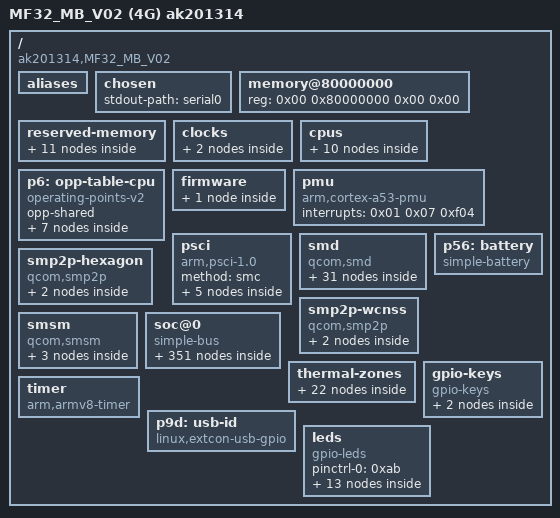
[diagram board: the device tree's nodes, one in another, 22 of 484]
/dts-v1/;

/ {
	interrupt-parent = <0x01>;
	#address-cells = <0x02>;
	#size-cells = <0x02>;
	chassis-type = "embedded";
	model = "MF32_MB_V02 (4G) ak201314";
	compatible = "ak201314,MF32_MB_V02", "qcom,msm8916";

	aliases {
		mmc0 = "/soc@0/mmc@7824000";
		mmc1 = "/soc@0/mmc@7864000";
		serial0 = "/soc@0/serial@78b0000";
	};

	chosen {
		stdout-path = "serial0";
	};

	memory@80000000 {
		device_type = "memory";
		reg = <0x00 0x80000000 0x00 0x00>;
	};

	reserved-memory {
		#address-cells = <0x02>;
		#size-cells = <0x02>;
		ranges;

		tz-apps@86000000 {
			reg = <0x00 0x86000000 0x00 0x300000>;
			no-map;
		};

		smem@86300000 {
			compatible = "qcom,smem";
			reg = <0x00 0x86300000 0x00 0x100000>;
			no-map;
			hwlocks = <&p2 0x03>;
			qcom,rpm-msg-ram = <0x03>;
		};

		hypervisor@86400000 {
			reg = <0x00 0x86400000 0x00 0x100000>;
			no-map;
		};

		tz@86500000 {
			reg = <0x00 0x86500000 0x00 0x180000>;
			no-map;
		};

		reserved@86680000 {
			reg = <0x00 0x86680000 0x00 0x80000>;
			no-map;
		};

		rmtfs@86700000 {
			compatible = "qcom,rmtfs-mem";
			reg = <0x00 0x86700000 0x00 0xe0000>;
			no-map;
			qcom,client-id = <0x01>;
		};

		rfsa@867e0000 {
			reg = <0x00 0x867e0000 0x00 0x20000>;
			no-map;
		};

		p64: mpss@86800000 {
			reg = <0x00 0x86800000 0x00 0x5500000>;
			no-map;
			phandle = <0x64>;
		};

		p9f: wcnss@8df00000 {
			reg = <0x00 0x8df00000 0x00 0x600000>;
			no-map;
			phandle = <0x9f>;
		};

		p55: venus@8e500000 {
			reg = <0x00 0x8e500000 0x00 0x100000>;
			no-map;
			phandle = <0x55>;
			status = "disabled";
		};

		p63: mba@8ea00000 {
			reg = <0x00 0x8ea00000 0x00 0x100000>;
			no-map;
			phandle = <0x63>;
		};
	};

	clocks {

		p1b: xo-board {
			compatible = "fixed-clock";
			#clock-cells = <0x00>;
			clock-frequency = <0x124f800>;
			phandle = <0x1b>;
		};

		p4a: sleep-clk {
			compatible = "fixed-clock";
			#clock-cells = <0x00>;
			clock-frequency = <0x8000>;
			phandle = <0x4a>;
		};
	};

	cpus {
		#address-cells = <0x01>;
		#size-cells = <0x00>;

		p3d: cpu@0 {
			device_type = "cpu";
			compatible = "arm,cortex-a53";
			reg = <0x00>;
			next-level-cache = <0x04>;
			enable-method = "psci";
			clocks = <&p5>;
			operating-points-v2 = <0x06>;
			#cooling-cells = <0x02>;
			power-domains = <&p7>;
			power-domain-names = "psci";
			qcom,acc = <0x08>;
			qcom,saw = <0x09>;
			phandle = <0x3d>;
		};

		p3e: cpu@1 {
			device_type = "cpu";
			compatible = "arm,cortex-a53";
			reg = <0x01>;
			next-level-cache = <0x04>;
			enable-method = "psci";
			clocks = <&p5>;
			operating-points-v2 = <0x06>;
			#cooling-cells = <0x02>;
			power-domains = <&pa>;
			power-domain-names = "psci";
			qcom,acc = <0x0b>;
			qcom,saw = <0x0c>;
			phandle = <0x3e>;
		};

		p3f: cpu@2 {
			device_type = "cpu";
			compatible = "arm,cortex-a53";
			reg = <0x02>;
			next-level-cache = <0x04>;
			enable-method = "psci";
			clocks = <&p5>;
			operating-points-v2 = <0x06>;
			#cooling-cells = <0x02>;
			power-domains = <&pd>;
			power-domain-names = "psci";
			qcom,acc = <0x0e>;
			qcom,saw = <0x0f>;
			phandle = <0x3f>;
		};

		p40: cpu@3 {
			device_type = "cpu";
			compatible = "arm,cortex-a53";
			reg = <0x03>;
			next-level-cache = <0x04>;
			enable-method = "psci";
			clocks = <&p5>;
			operating-points-v2 = <0x06>;
			#cooling-cells = <0x02>;
			power-domains = <&p10>;
			power-domain-names = "psci";
			qcom,acc = <0x11>;
			qcom,saw = <0x12>;
			phandle = <0x40>;
		};

		p4: l2-cache {
			compatible = "cache";
			cache-level = <0x02>;
			phandle = <0x04>;
		};

		idle-states {
			entry-method = "psci";

			p18: cpu-sleep-0 {
				compatible = "arm,idle-state";
				idle-state-name = "standalone-power-collapse";
				arm,psci-suspend-param = <0x40000002>;
				entry-latency-us = <0x82>;
				exit-latency-us = <0x96>;
				min-residency-us = <0x7d0>;
				local-timer-stop;
				phandle = <0x18>;
			};
		};

		domain-idle-states {

			p19: cluster-retention {
				compatible = "domain-idle-state";
				arm,psci-suspend-param = <0x41000012>;
				entry-latency-us = <0x1f4>;
				exit-latency-us = <0x1f4>;
				min-residency-us = <0x7d0>;
				phandle = <0x19>;
			};

			p1a: cluster-gdhs {
				compatible = "domain-idle-state";
				arm,psci-suspend-param = <0x41000032>;
				entry-latency-us = <0x7d0>;
				exit-latency-us = <0x7d0>;
				min-residency-us = <0x1770>;
				phandle = <0x1a>;
			};
		};
	};

	p6: opp-table-cpu {
		compatible = "operating-points-v2";
		opp-shared;
		phandle = <0x06>;

		opp-200000000 {
			opp-hz = <0x00 0xbebc200>;
		};

		opp-400000000 {
			opp-hz = <0x00 0x17d78400>;
		};

		opp-800000000 {
			opp-hz = <0x00 0x2faf0800>;
		};

		opp-998400000 {
			opp-hz = <0x00 0x3b826000>;
		};

		opp-1094400000 {
			opp-hz = <0x00 0x413b3800>;
		};

		opp-1152000000 {
			opp-hz = <0x00 0x44aa2000>;
		};

		opp-1209600000 {
			opp-hz = <0x00 0x48190800>;
		};
	};

	firmware {

		p61: scm {
			compatible = "qcom,scm-msm8916", "qcom,scm";
			clocks = <&p13 0x68 &p13 0x67 &p13 0x66>;
			clock-names = "core", "bus", "iface";
			#reset-cells = <0x01>;
			qcom,dload-mode = <0x14 0x6100>;
			phandle = <0x61>;
		};
	};

	pmu {
		compatible = "arm,cortex-a53-pmu";
		interrupts = <0x01 0x07 0xf04>;
	};

	psci {
		compatible = "arm,psci-1.0";
		method = "smc";

		p7: power-domain-cpu0 {
			#power-domain-cells = <0x00>;
			power-domains = <&p17>;
			domain-idle-states = <0x18>;
			phandle = <0x07>;
		};

		pa: power-domain-cpu1 {
			#power-domain-cells = <0x00>;
			power-domains = <&p17>;
			domain-idle-states = <0x18>;
			phandle = <0x0a>;
		};

		pd: power-domain-cpu2 {
			#power-domain-cells = <0x00>;
			power-domains = <&p17>;
			domain-idle-states = <0x18>;
			phandle = <0x0d>;
		};

		p10: power-domain-cpu3 {
			#power-domain-cells = <0x00>;
			power-domains = <&p17>;
			domain-idle-states = <0x18>;
			phandle = <0x10>;
		};

		p17: power-domain-cluster {
			#power-domain-cells = <0x00>;
			domain-idle-states = <0x19 0x1a>;
			phandle = <0x17>;
		};
	};

	smd {
		compatible = "qcom,smd";

		rpm {
			interrupts = <0x00 0xa8 0x01>;
			qcom,ipc = <0x05 0x08 0x00>;
			qcom,smd-edge = <0x0f>;

			rpm-requests {
				compatible = "qcom,rpm-msm8916";
				qcom,smd-channels = "rpm_requests";

				p1f: clock-controller {
					compatible = "qcom,rpmcc-msm8916", "qcom,rpmcc";
					#clock-cells = <0x01>;
					clocks = <&p1b>;
					clock-names = "xo";
					phandle = <0x1f>;
				};

				p5f: power-controller {
					compatible = "qcom,msm8916-rpmpd";
					#power-domain-cells = <0x01>;
					operating-points-v2 = <0x1c>;
					phandle = <0x5f>;

					p1c: opp-table {
						compatible = "operating-points-v2";
						phandle = <0x1c>;

						opp1 {
							opp-level = <0x01>;
						};

						opp2 {
							opp-level = <0x02>;
						};

						opp3 {
							opp-level = <0x03>;
						};

						opp4 {
							opp-level = <0x04>;
						};

						opp5 {
							opp-level = <0x05>;
						};

						opp6 {
							opp-level = <0x06>;
						};
					};
				};

				regulators {
					compatible = "qcom,rpm-pm8916-regulators";
					vdd_l1_l2_l3-supply = <0x1d>;
					vdd_l4_l5_l6-supply = <0x1e>;
					vdd_l7-supply = <0x1e>;

					p1d: s3 {
						regulator-min-microvolt = <0x124f80>;
						regulator-max-microvolt = <0x13d620>;
						phandle = <0x1d>;
					};

					p1e: s4 {
						regulator-min-microvolt = <0x1b7740>;
						regulator-max-microvolt = <0x200b20>;
						phandle = <0x1e>;
					};

					l1 {
						regulator-min-microvolt = <0x12b128>;
						regulator-max-microvolt = <0x12b128>;
					};

					p4f: l2 {
						regulator-min-microvolt = <0x124f80>;
						regulator-max-microvolt = <0x124f80>;
						phandle = <0x4f>;
					};

					l4 {
						regulator-min-microvolt = <0x1f47d0>;
						regulator-max-microvolt = <0x1f47d0>;
					};

					p5c: l5 {
						regulator-min-microvolt = <0x1b7740>;
						regulator-max-microvolt = <0x1b7740>;
						phandle = <0x5c>;
					};

					p50: l6 {
						regulator-min-microvolt = <0x1b7740>;
						regulator-max-microvolt = <0x1b7740>;
						phandle = <0x50>;
					};

					p62: l7 {
						regulator-min-microvolt = <0x1b7740>;
						regulator-max-microvolt = <0x1b7740>;
						phandle = <0x62>;
					};

					p70: l8 {
						regulator-min-microvolt = <0x2b7cd0>;
						regulator-max-microvolt = <0x2c4020>;
						phandle = <0x70>;
					};

					pa3: l9 {
						regulator-min-microvolt = <0x325aa0>;
						regulator-max-microvolt = <0x325aa0>;
						phandle = <0xa3>;
					};

					l10 {
						regulator-min-microvolt = <0x2932e0>;
						regulator-max-microvolt = <0x2ab980>;
					};

					p77: l11 {
						regulator-min-microvolt = <0x1b7740>;
						regulator-max-microvolt = <0x2d0370>;
						regulator-system-load = <0x30d40>;
						regulator-allow-set-load;
						phandle = <0x77>;
					};

					p78: l12 {
						regulator-min-microvolt = <0x1b7740>;
						regulator-max-microvolt = <0x2d0370>;
						phandle = <0x78>;
					};

					p5d: l13 {
						regulator-min-microvolt = <0x2eebb8>;
						regulator-max-microvolt = <0x2eebb8>;
						phandle = <0x5d>;
					};

					l14 {
						regulator-min-microvolt = <0x1b7740>;
						regulator-max-microvolt = <0x325aa0>;
					};

					l15 {
						regulator-min-microvolt = <0x1b7740>;
						regulator-max-microvolt = <0x325aa0>;
					};

					l16 {
						regulator-min-microvolt = <0x1b7740>;
						regulator-max-microvolt = <0x325aa0>;
					};

					l17 {
						regulator-min-microvolt = <0x2b7cd0>;
						regulator-max-microvolt = <0x2b7cd0>;
					};

					l18 {
						regulator-min-microvolt = <0x2932e0>;
						regulator-max-microvolt = <0x2932e0>;
					};
				};
			};
		};
	};

	smp2p-hexagon {
		compatible = "qcom,smp2p";
		qcom,smem = <0x1b3 0x1ac>;
		interrupts = <0x00 0x1b 0x01>;
		qcom,ipc = <0x05 0x08 0x0e>;
		qcom,local-pid = <0x00>;
		qcom,remote-pid = <0x01>;

		p60: master-kernel {
			qcom,entry-name = "master-kernel";
			#qcom,smem-state-cells = <0x01>;
			phandle = <0x60>;
		};

		p5e: slave-kernel {
			qcom,entry-name = "slave-kernel";
			interrupt-controller;
			#interrupt-cells = <0x02>;
			phandle = <0x5e>;
		};
	};

	smp2p-wcnss {
		compatible = "qcom,smp2p";
		qcom,smem = <0x1c3 0x1af>;
		interrupts = <0x00 0x8f 0x01>;
		qcom,ipc = <0x05 0x08 0x12>;
		qcom,local-pid = <0x00>;
		qcom,remote-pid = <0x04>;

		pa1: master-kernel {
			qcom,entry-name = "master-kernel";
			#qcom,smem-state-cells = <0x01>;
			phandle = <0xa1>;
		};

		pa0: slave-kernel {
			qcom,entry-name = "slave-kernel";
			interrupt-controller;
			#interrupt-cells = <0x02>;
			phandle = <0xa0>;
		};
	};

	smsm {
		compatible = "qcom,smsm";
		#address-cells = <0x01>;
		#size-cells = <0x00>;
		qcom,ipc-1 = <0x05 0x08 0x0d>;
		qcom,ipc-3 = <0x05 0x08 0x13>;

		p66: apps@0 {
			reg = <0x00>;
			#qcom,smem-state-cells = <0x01>;
			phandle = <0x66>;
		};

		p65: hexagon@1 {
			reg = <0x01>;
			interrupts = <0x00 0x1a 0x01>;
			interrupt-controller;
			#interrupt-cells = <0x02>;
			phandle = <0x65>;
		};

		wcnss@6 {
			reg = <0x06>;
			interrupts = <0x00 0x90 0x01>;
			interrupt-controller;
			#interrupt-cells = <0x02>;
		};
	};

	soc@0 {
		#address-cells = <0x01>;
		#size-cells = <0x01>;
		ranges = <0x00 0x00 0x00 0xffffffff>;
		compatible = "simple-bus";

		rng@22000 {
			compatible = "qcom,prng";
			reg = <0x22000 0x200>;
			clocks = <&p13 0x79>;
			clock-names = "core";
		};

		restart@4ab000 {
			compatible = "qcom,pshold";
			reg = <0x4ab000 0x04>;
		};

		qfprom@5c000 {
			compatible = "qcom,msm8916-qfprom", "qcom,qfprom";
			reg = <0x5c000 0x1000>;
			#address-cells = <0x01>;
			#size-cells = <0x01>;

			p21: base1@d0 {
				reg = <0xd0 0x01>;
				bits = <0x00 0x07>;
				phandle = <0x21>;
			};

			p23: s0-p1@d0 {
				reg = <0xd0 0x02>;
				bits = <0x07 0x05>;
				phandle = <0x23>;
			};

			p24: s0-p2@d1 {
				reg = <0xd1 0x02>;
				bits = <0x04 0x05>;
				phandle = <0x24>;
			};

			p25: s1-p1@d2 {
				reg = <0xd2 0x01>;
				bits = <0x01 0x05>;
				phandle = <0x25>;
			};

			p26: s1-p2@d2 {
				reg = <0xd2 0x02>;
				bits = <0x06 0x05>;
				phandle = <0x26>;
			};

			p27: s2-p1@d3 {
				reg = <0xd3 0x01>;
				bits = <0x03 0x05>;
				phandle = <0x27>;
			};

			p28: s2-p2@d4 {
				reg = <0xd4 0x01>;
				bits = <0x00 0x05>;
				phandle = <0x28>;
			};

			p29: s4-p1@d4 {
				reg = <0xd4 0x02>;
				bits = <0x05 0x05>;
				phandle = <0x29>;
			};

			p2a: s4-p2@d5 {
				reg = <0xd5 0x01>;
				bits = <0x02 0x05>;
				phandle = <0x2a>;
			};

			p2b: s5-p1@d5 {
				reg = <0xd5 0x02>;
				bits = <0x07 0x05>;
				phandle = <0x2b>;
			};

			p2c: s5-p2@d6 {
				reg = <0xd6 0x02>;
				bits = <0x04 0x05>;
				phandle = <0x2c>;
			};

			p22: base2@d7 {
				reg = <0xd7 0x01>;
				bits = <0x01 0x07>;
				phandle = <0x22>;
			};

			p20: mode@ec {
				reg = <0xef 0x01>;
				bits = <0x05 0x03>;
				phandle = <0x20>;
			};
		};

		p3: sram@60000 {
			compatible = "qcom,rpm-msg-ram";
			reg = <0x60000 0x8000>;
			phandle = <0x03>;
		};

		sram@290000 {
			compatible = "qcom,msm8916-rpm-stats";
			reg = <0x290000 0x10000>;
		};

		interconnect@400000 {
			compatible = "qcom,msm8916-bimc";
			reg = <0x400000 0x62000>;
			#interconnect-cells = <0x01>;
			clock-names = "bus", "bus_a";
			clocks = <&p1f 0x06 &p1f 0x07>;
		};

		pa6: thermal-sensor@4a9000 {
			compatible = "qcom,msm8916-tsens", "qcom,tsens-v0_1";
			reg = <0x4a9000 0x1000 0x4a8000 0x1000>;
			nvmem-cells = <0x20 0x21 0x22 0x23 0x24 0x25 0x26 0x27 0x28 0x29 0x2a 0x2b 0x2c>;
			nvmem-cell-names = "mode", "base1", "base2", "s0_p1", "s0_p2", "s1_p1", "s1_p2", "s2_p1", "s2_p2", "s4_p1", "s4_p2", "s5_p1", "s5_p2";
			#qcom,sensors = <0x05>;
			interrupts = <0x00 0xb8 0x04>;
			interrupt-names = "uplow";
			#thermal-sensor-cells = <0x01>;
			phandle = <0xa6>;
		};

		interconnect@500000 {
			compatible = "qcom,msm8916-pcnoc";
			reg = <0x500000 0x11000>;
			#interconnect-cells = <0x01>;
			clock-names = "bus", "bus_a";
			clocks = <&p1f 0x02 &p1f 0x03>;
		};

		interconnect@580000 {
			compatible = "qcom,msm8916-snoc";
			reg = <0x580000 0x14000>;
			#interconnect-cells = <0x01>;
			clock-names = "bus", "bus_a";
			clocks = <&p1f 0x04 &p1f 0x05>;
		};

		stm@802000 {
			compatible = "arm,coresight-stm", "arm,primecell";
			reg = <0x802000 0x1000 0x9280000 0x180000>;
			reg-names = "stm-base", "stm-stimulus-base";
			clocks = <&p1f 0x08 &p1f 0x09>;
			clock-names = "apb_pclk", "atclk";
			status = "disabled";

			out-ports {

				port {

					p30: endpoint {
						remote-endpoint = <0x2d>;
						phandle = <0x30>;
					};
				};
			};
		};

		cti@810000 {
			compatible = "arm,coresight-cti", "arm,primecell";
			reg = <0x810000 0x1000>;
			clocks = <&p1f 0x08>;
			clock-names = "apb_pclk";
			status = "disabled";
		};

		cti@811000 {
			compatible = "arm,coresight-cti", "arm,primecell";
			reg = <0x811000 0x1000>;
			clocks = <&p1f 0x08>;
			clock-names = "apb_pclk";
			status = "disabled";
		};

		tpiu@820000 {
			compatible = "arm,coresight-tpiu", "arm,primecell";
			reg = <0x820000 0x1000>;
			clocks = <&p1f 0x08 &p1f 0x09>;
			clock-names = "apb_pclk", "atclk";
			status = "disabled";

			in-ports {

				port {

					p33: endpoint {
						remote-endpoint = <0x2e>;
						phandle = <0x33>;
					};
				};
			};
		};

		funnel@821000 {
			compatible = "arm,coresight-dynamic-funnel", "arm,primecell";
			reg = <0x821000 0x1000>;
			clocks = <&p1f 0x08 &p1f 0x09>;
			clock-names = "apb_pclk", "atclk";
			status = "disabled";

			in-ports {
				#address-cells = <0x01>;
				#size-cells = <0x00>;

				port@4 {
					reg = <0x04>;

					p3c: endpoint {
						remote-endpoint = <0x2f>;
						phandle = <0x3c>;
					};
				};

				port@7 {
					reg = <0x07>;

					p2d: endpoint {
						remote-endpoint = <0x30>;
						phandle = <0x2d>;
					};
				};
			};

			out-ports {

				port {

					p35: endpoint {
						remote-endpoint = <0x31>;
						phandle = <0x35>;
					};
				};
			};
		};

		replicator@824000 {
			compatible = "arm,coresight-dynamic-replicator", "arm,primecell";
			reg = <0x824000 0x1000>;
			clocks = <&p1f 0x08 &p1f 0x09>;
			clock-names = "apb_pclk", "atclk";
			status = "disabled";

			out-ports {
				#address-cells = <0x01>;
				#size-cells = <0x00>;

				port@0 {
					reg = <0x00>;

					p37: endpoint {
						remote-endpoint = <0x32>;
						phandle = <0x37>;
					};
				};

				port@1 {
					reg = <0x01>;

					p2e: endpoint {
						remote-endpoint = <0x33>;
						phandle = <0x2e>;
					};
				};
			};

			in-ports {

				port {

					p36: endpoint {
						remote-endpoint = <0x34>;
						phandle = <0x36>;
					};
				};
			};
		};

		etf@825000 {
			compatible = "arm,coresight-tmc", "arm,primecell";
			reg = <0x825000 0x1000>;
			clocks = <&p1f 0x08 &p1f 0x09>;
			clock-names = "apb_pclk", "atclk";
			status = "disabled";

			in-ports {

				port {

					p31: endpoint {
						remote-endpoint = <0x35>;
						phandle = <0x31>;
					};
				};
			};

			out-ports {

				port {

					p34: endpoint {
						remote-endpoint = <0x36>;
						phandle = <0x34>;
					};
				};
			};
		};

		etr@826000 {
			compatible = "arm,coresight-tmc", "arm,primecell";
			reg = <0x826000 0x1000>;
			clocks = <&p1f 0x08 &p1f 0x09>;
			clock-names = "apb_pclk", "atclk";
			status = "disabled";

			in-ports {

				port {

					p32: endpoint {
						remote-endpoint = <0x37>;
						phandle = <0x32>;
					};
				};
			};
		};

		funnel@841000 {
			compatible = "arm,coresight-dynamic-funnel", "arm,primecell";
			reg = <0x841000 0x1000>;
			clocks = <&p1f 0x08 &p1f 0x09>;
			clock-names = "apb_pclk", "atclk";
			status = "disabled";

			in-ports {
				#address-cells = <0x01>;
				#size-cells = <0x00>;

				port@0 {
					reg = <0x00>;

					p45: endpoint {
						remote-endpoint = <0x38>;
						phandle = <0x45>;
					};
				};

				port@1 {
					reg = <0x01>;

					p46: endpoint {
						remote-endpoint = <0x39>;
						phandle = <0x46>;
					};
				};

				port@2 {
					reg = <0x02>;

					p47: endpoint {
						remote-endpoint = <0x3a>;
						phandle = <0x47>;
					};
				};

				port@3 {
					reg = <0x03>;

					p48: endpoint {
						remote-endpoint = <0x3b>;
						phandle = <0x48>;
					};
				};
			};

			out-ports {

				port {

					p2f: endpoint {
						remote-endpoint = <0x3c>;
						phandle = <0x2f>;
					};
				};
			};
		};

		debug@850000 {
			compatible = "arm,coresight-cpu-debug", "arm,primecell";
			reg = <0x850000 0x1000>;
			clocks = <&p1f 0x08>;
			clock-names = "apb_pclk";
			cpu = <0x3d>;
			status = "disabled";
		};

		debug@852000 {
			compatible = "arm,coresight-cpu-debug", "arm,primecell";
			reg = <0x852000 0x1000>;
			clocks = <&p1f 0x08>;
			clock-names = "apb_pclk";
			cpu = <0x3e>;
			status = "disabled";
		};

		debug@854000 {
			compatible = "arm,coresight-cpu-debug", "arm,primecell";
			reg = <0x854000 0x1000>;
			clocks = <&p1f 0x08>;
			clock-names = "apb_pclk";
			cpu = <0x3f>;
			status = "disabled";
		};

		debug@856000 {
			compatible = "arm,coresight-cpu-debug", "arm,primecell";
			reg = <0x856000 0x1000>;
			clocks = <&p1f 0x08>;
			clock-names = "apb_pclk";
			cpu = <0x40>;
			status = "disabled";
		};

		cti@858000 {
			compatible = "arm,coresight-cti-v8-arch", "arm,coresight-cti", "arm,primecell";
			reg = <0x858000 0x1000>;
			clocks = <&p1f 0x08>;
			clock-names = "apb_pclk";
			cpu = <0x3d>;
			arm,cs-dev-assoc = <0x41>;
			status = "disabled";
		};

		cti@859000 {
			compatible = "arm,coresight-cti-v8-arch", "arm,coresight-cti", "arm,primecell";
			reg = <0x859000 0x1000>;
			clocks = <&p1f 0x08>;
			clock-names = "apb_pclk";
			cpu = <0x3e>;
			arm,cs-dev-assoc = <0x42>;
			status = "disabled";
		};

		cti@85a000 {
			compatible = "arm,coresight-cti-v8-arch", "arm,coresight-cti", "arm,primecell";
			reg = <0x85a000 0x1000>;
			clocks = <&p1f 0x08>;
			clock-names = "apb_pclk";
			cpu = <0x3f>;
			arm,cs-dev-assoc = <0x43>;
			status = "disabled";
		};

		cti@85b000 {
			compatible = "arm,coresight-cti-v8-arch", "arm,coresight-cti", "arm,primecell";
			reg = <0x85b000 0x1000>;
			clocks = <&p1f 0x08>;
			clock-names = "apb_pclk";
			cpu = <0x40>;
			arm,cs-dev-assoc = <0x44>;
			status = "disabled";
		};

		p41: etm@85c000 {
			compatible = "arm,coresight-etm4x", "arm,primecell";
			reg = <0x85c000 0x1000>;
			clocks = <&p1f 0x08 &p1f 0x09>;
			clock-names = "apb_pclk", "atclk";
			arm,coresight-loses-context-with-cpu;
			cpu = <0x3d>;
			status = "disabled";
			phandle = <0x41>;

			out-ports {

				port {

					p38: endpoint {
						remote-endpoint = <0x45>;
						phandle = <0x38>;
					};
				};
			};
		};

		p42: etm@85d000 {
			compatible = "arm,coresight-etm4x", "arm,primecell";
			reg = <0x85d000 0x1000>;
			clocks = <&p1f 0x08 &p1f 0x09>;
			clock-names = "apb_pclk", "atclk";
			arm,coresight-loses-context-with-cpu;
			cpu = <0x3e>;
			status = "disabled";
			phandle = <0x42>;

			out-ports {

				port {

					p39: endpoint {
						remote-endpoint = <0x46>;
						phandle = <0x39>;
					};
				};
			};
		};

		p43: etm@85e000 {
			compatible = "arm,coresight-etm4x", "arm,primecell";
			reg = <0x85e000 0x1000>;
			clocks = <&p1f 0x08 &p1f 0x09>;
			clock-names = "apb_pclk", "atclk";
			arm,coresight-loses-context-with-cpu;
			cpu = <0x3f>;
			status = "disabled";
			phandle = <0x43>;

			out-ports {

				port {

					p3a: endpoint {
						remote-endpoint = <0x47>;
						phandle = <0x3a>;
					};
				};
			};
		};

		p44: etm@85f000 {
			compatible = "arm,coresight-etm4x", "arm,primecell";
			reg = <0x85f000 0x1000>;
			clocks = <&p1f 0x08 &p1f 0x09>;
			clock-names = "apb_pclk", "atclk";
			arm,coresight-loses-context-with-cpu;
			cpu = <0x40>;
			status = "disabled";
			phandle = <0x44>;

			out-ports {

				port {

					p3b: endpoint {
						remote-endpoint = <0x48>;
						phandle = <0x3b>;
					};
				};
			};
		};

		p49: pinctrl@1000000 {
			compatible = "qcom,msm8916-pinctrl";
			reg = <0x1000000 0x300000>;
			interrupts = <0x00 0xd0 0x04>;
			gpio-controller;
			gpio-ranges = <0x49 0x00 0x00 0x7a>;
			#gpio-cells = <0x02>;
			interrupt-controller;
			#interrupt-cells = <0x02>;
			phandle = <0x49>;

			p80: blsp1-uart1-default-state {
				pins = "gpio0", "gpio1", "gpio2", "gpio3";
				function = "blsp_uart1";
				drive-strength = <0x10>;
				bias-disable;
				phandle = <0x80>;
			};

			p81: blsp1-uart1-sleep-state {
				pins = "gpio0", "gpio1", "gpio2", "gpio3";
				function = "gpio";
				drive-strength = <0x02>;
				bias-pull-down;
				phandle = <0x81>;
			};

			p82: blsp1-uart2-default-state {
				pins = "gpio4", "gpio5";
				function = "blsp_uart2";
				drive-strength = <0x10>;
				bias-disable;
				phandle = <0x82>;
			};

			p83: blsp1-uart2-sleep-state {
				pins = "gpio4", "gpio5";
				function = "gpio";
				drive-strength = <0x02>;
				bias-pull-down;
				phandle = <0x83>;
			};

			p86: spi1-default-state {
				phandle = <0x86>;

				spi-pins {
					pins = "gpio0", "gpio1", "gpio3";
					function = "blsp_spi1";
					drive-strength = <0x0c>;
					bias-disable;
				};

				cs-pins {
					pins = "gpio2";
					function = "gpio";
					drive-strength = <0x10>;
					bias-disable;
					output-high;
				};
			};

			p87: spi1-sleep-state {
				pins = "gpio0", "gpio1", "gpio2", "gpio3";
				function = "gpio";
				drive-strength = <0x02>;
				bias-pull-down;
				phandle = <0x87>;
			};

			p8a: spi2-default-state {
				phandle = <0x8a>;

				spi-pins {
					pins = "gpio4", "gpio5", "gpio7";
					function = "blsp_spi2";
					drive-strength = <0x0c>;
					bias-disable;
				};

				cs-pins {
					pins = "gpio6";
					function = "gpio";
					drive-strength = <0x10>;
					bias-disable;
					output-high;
				};
			};

			p8b: spi2-sleep-state {
				pins = "gpio4", "gpio5", "gpio6", "gpio7";
				function = "gpio";
				drive-strength = <0x02>;
				bias-pull-down;
				phandle = <0x8b>;
			};

			p8e: spi3-default-state {
				phandle = <0x8e>;

				spi-pins {
					pins = "gpio8", "gpio9", "gpio11";
					function = "blsp_spi3";
					drive-strength = <0x0c>;
					bias-disable;
				};

				cs-pins {
					pins = "gpio10";
					function = "gpio";
					drive-strength = <0x10>;
					bias-disable;
					output-high;
				};
			};

			p8f: spi3-sleep-state {
				pins = "gpio8", "gpio9", "gpio10", "gpio11";
				function = "gpio";
				drive-strength = <0x02>;
				bias-pull-down;
				phandle = <0x8f>;
			};

			p92: spi4-default-state {
				phandle = <0x92>;

				spi-pins {
					pins = "gpio12", "gpio13", "gpio15";
					function = "blsp_spi4";
					drive-strength = <0x0c>;
					bias-disable;
				};

				cs-pins {
					pins = "gpio14";
					function = "gpio";
					drive-strength = <0x10>;
					bias-disable;
					output-high;
				};
			};

			p93: spi4-sleep-state {
				pins = "gpio12", "gpio13", "gpio14", "gpio15";
				function = "gpio";
				drive-strength = <0x02>;
				bias-pull-down;
				phandle = <0x93>;
			};

			p96: spi5-default-state {
				phandle = <0x96>;

				spi-pins {
					pins = "gpio16", "gpio17", "gpio19";
					function = "blsp_spi5";
					drive-strength = <0x0c>;
					bias-disable;
				};

				cs-pins {
					pins = "gpio18";
					function = "gpio";
					drive-strength = <0x10>;
					bias-disable;
					output-high;
				};
			};

			p97: spi5-sleep-state {
				pins = "gpio16", "gpio17", "gpio18", "gpio19";
				function = "gpio";
				drive-strength = <0x02>;
				bias-pull-down;
				phandle = <0x97>;
			};

			p9a: spi6-default-state {
				phandle = <0x9a>;

				spi-pins {
					pins = "gpio20", "gpio21", "gpio23";
					function = "blsp_spi6";
					drive-strength = <0x0c>;
					bias-disable;
				};

				cs-pins {
					pins = "gpio22";
					function = "gpio";
					drive-strength = <0x10>;
					bias-disable;
					output-high;
				};
			};

			p9b: spi6-sleep-state {
				pins = "gpio20", "gpio21", "gpio22", "gpio23";
				function = "gpio";
				drive-strength = <0x02>;
				bias-pull-down;
				phandle = <0x9b>;
			};

			p84: i2c1-default-state {
				pins = "gpio2", "gpio3";
				function = "blsp_i2c1";
				drive-strength = <0x02>;
				bias-disable;
				phandle = <0x84>;
			};

			p85: i2c1-sleep-state {
				pins = "gpio2", "gpio3";
				function = "gpio";
				drive-strength = <0x02>;
				bias-disable;
				phandle = <0x85>;
			};

			p88: i2c2-default-state {
				pins = "gpio6", "gpio7";
				function = "blsp_i2c2";
				drive-strength = <0x02>;
				bias-disable;
				phandle = <0x88>;
			};

			p89: i2c2-sleep-state {
				pins = "gpio6", "gpio7";
				function = "gpio";
				drive-strength = <0x02>;
				bias-disable;
				phandle = <0x89>;
			};

			p8c: i2c3-default-state {
				pins = "gpio10", "gpio11";
				function = "blsp_i2c3";
				drive-strength = <0x02>;
				bias-disable;
				phandle = <0x8c>;
			};

			p8d: i2c3-sleep-state {
				pins = "gpio10", "gpio11";
				function = "gpio";
				drive-strength = <0x02>;
				bias-disable;
				phandle = <0x8d>;
			};

			p90: i2c4-default-state {
				pins = "gpio14", "gpio15";
				function = "blsp_i2c4";
				drive-strength = <0x02>;
				bias-disable;
				phandle = <0x90>;
			};

			p91: i2c4-sleep-state {
				pins = "gpio14", "gpio15";
				function = "gpio";
				drive-strength = <0x02>;
				bias-disable;
				phandle = <0x91>;
			};

			p94: i2c5-default-state {
				pins = "gpio18", "gpio19";
				function = "blsp_i2c5";
				drive-strength = <0x02>;
				bias-disable;
				phandle = <0x94>;
			};

			p95: i2c5-sleep-state {
				pins = "gpio18", "gpio19";
				function = "gpio";
				drive-strength = <0x02>;
				bias-disable;
				phandle = <0x95>;
			};

			p98: i2c6-default-state {
				pins = "gpio22", "gpio23";
				function = "blsp_i2c6";
				drive-strength = <0x02>;
				bias-disable;
				phandle = <0x98>;
			};

			p99: i2c6-sleep-state {
				pins = "gpio22", "gpio23";
				function = "gpio";
				drive-strength = <0x02>;
				bias-disable;
				phandle = <0x99>;
			};

			pmx-sdc1-clk-state {

				p71: clk-on-pins {
					pins = "sdc1_clk";
					bias-disable;
					drive-strength = <0x10>;
					phandle = <0x71>;
				};

				p74: clk-off-pins {
					pins = "sdc1_clk";
					bias-disable;
					drive-strength = <0x02>;
					phandle = <0x74>;
				};
			};

			pmx-sdc1-cmd-state {

				p72: cmd-on-pins {
					pins = "sdc1_cmd";
					bias-pull-up;
					drive-strength = <0x0a>;
					phandle = <0x72>;
				};

				p75: cmd-off-pins {
					pins = "sdc1_cmd";
					bias-pull-up;
					drive-strength = <0x02>;
					phandle = <0x75>;
				};
			};

			pmx-sdc1-data-state {

				p73: data-on-pins {
					pins = "sdc1_data";
					bias-pull-up;
					drive-strength = <0x0a>;
					phandle = <0x73>;
				};

				p76: data-off-pins {
					pins = "sdc1_data";
					bias-pull-up;
					drive-strength = <0x02>;
					phandle = <0x76>;
				};
			};

			pmx-sdc2-clk-state {

				p79: clk-on-pins {
					pins = "sdc2_clk";
					bias-disable;
					drive-strength = <0x10>;
					phandle = <0x79>;
				};

				p7c: clk-off-pins {
					pins = "sdc2_clk";
					bias-disable;
					drive-strength = <0x02>;
					phandle = <0x7c>;
				};
			};

			pmx-sdc2-cmd-state {

				p7a: cmd-on-pins {
					pins = "sdc2_cmd";
					bias-pull-up;
					drive-strength = <0x0a>;
					phandle = <0x7a>;
				};

				p7d: cmd-off-pins {
					pins = "sdc2_cmd";
					bias-pull-up;
					drive-strength = <0x02>;
					phandle = <0x7d>;
				};
			};

			pmx-sdc2-data-state {

				p7b: data-on-pins {
					pins = "sdc2_data";
					bias-pull-up;
					drive-strength = <0x0a>;
					phandle = <0x7b>;
				};

				p7e: data-off-pins {
					pins = "sdc2_data";
					bias-pull-up;
					drive-strength = <0x02>;
					phandle = <0x7e>;
				};
			};

			p1000: pmx-sdc2-cd-pin-state {
				phandle = <0x1000>;

				cd-on-pins {
					pins = "gpio38";
					function = "gpio";
					drive-strength = <0x02>;
					bias-pull-up;
				};

				cd-off-pins {
					pins = "gpio38";
					function = "gpio";
					drive-strength = <0x02>;
					bias-disable;
				};
			};

			cdc-pdm-lines-state {

				p68: pdm-lines-on-pins {
					pins = "gpio63", "gpio64", "gpio65", "gpio66", "gpio67", "gpio68";
					function = "cdc_pdm0";
					drive-strength = <0x08>;
					bias-disable;
					phandle = <0x68>;
				};

				p69: pdm-lines-off-pins {
					pins = "gpio63", "gpio64", "gpio65", "gpio66", "gpio67", "gpio68";
					function = "cdc_pdm0";
					drive-strength = <0x02>;
					bias-pull-down;
					phandle = <0x69>;
				};
			};

			ext-pri-tlmm-lines-state {

				ext-pa-on-pins {
					pins = "gpio113", "gpio114", "gpio115", "gpio116";
					function = "pri_mi2s";
					drive-strength = <0x08>;
					bias-disable;
				};

				ext-pa-off-pins {
					pins = "gpio113", "gpio114", "gpio115", "gpio116";
					function = "pri_mi2s";
					drive-strength = <0x02>;
					bias-disable;
				};
			};

			ext-pri-ws-line-state {

				ext-pa-on-pins {
					pins = "gpio110";
					function = "pri_mi2s_ws";
					drive-strength = <0x08>;
					bias-disable;
				};

				ext-pa-off-pins {
					pins = "gpio110";
					function = "pri_mi2s_ws";
					drive-strength = <0x02>;
					bias-disable;
				};
			};

			ext-mclk-tlmm-lines-state {

				mclk-lines-on-pins {
					pins = "gpio116";
					function = "pri_mi2s";
					drive-strength = <0x08>;
					bias-disable;
				};

				mclk-lines-off-pins {
					pins = "gpio116";
					function = "pri_mi2s";
					drive-strength = <0x02>;
					bias-disable;
				};
			};

			ext-sec-tlmm-lines-state {

				tlmm-lines-on-pins {
					pins = "gpio112", "gpio117", "gpio118", "gpio119";
					function = "sec_mi2s";
					drive-strength = <0x08>;
					bias-disable;
				};

				tlmm-lines-off-pins {
					pins = "gpio112", "gpio117", "gpio118", "gpio119";
					function = "sec_mi2s";
					drive-strength = <0x02>;
					bias-disable;
				};
			};

			cdc-dmic-lines-on-state {

				clk-pins {
					pins = "gpio0";
					function = "dmic0_clk";
					drive-strength = <0x08>;
				};

				data-pins {
					pins = "gpio1";
					function = "dmic0_data";
					drive-strength = <0x08>;
				};
			};

			cdc-dmic-lines-off-state {

				clk-pins {
					pins = "gpio0";
					function = "dmic0_clk";
					drive-strength = <0x02>;
					bias-disable;
				};

				data-pins {
					pins = "gpio1";
					function = "dmic0_data";
					drive-strength = <0x02>;
					bias-disable;
				};
			};

			pa2: wcnss-active-state {
				pins = "gpio40", "gpio41", "gpio42", "gpio43", "gpio44";
				function = "wcss_wlan";
				drive-strength = <0x06>;
				bias-pull-up;
				phandle = <0xa2>;
			};

			p52: cci0-default-state {
				pins = "gpio29", "gpio30";
				function = "cci_i2c";
				drive-strength = <0x10>;
				bias-disable;
				phandle = <0x52>;
			};

			camera-front-default-state {

				pwdn-pins {
					pins = "gpio33";
					function = "gpio";
					drive-strength = <0x10>;
					bias-disable;
				};

				rst-pins {
					pins = "gpio28";
					function = "gpio";
					drive-strength = <0x10>;
					bias-disable;
				};

				mclk1-pins {
					pins = "gpio27";
					function = "cam_mclk1";
					drive-strength = <0x10>;
					bias-disable;
				};
			};

			camera-rear-default-state {

				pwdn-pins {
					pins = "gpio34";
					function = "gpio";
					drive-strength = <0x10>;
					bias-disable;
				};

				rst-pins {
					pins = "gpio35";
					function = "gpio";
					drive-strength = <0x10>;
					bias-disable;
				};

				mclk0-pins {
					pins = "gpio26";
					function = "cam_mclk0";
					drive-strength = <0x10>;
					bias-disable;
				};
			};

			paa: tlmm-gpio-key-active {
				pins = "gpio37";
				function = "gpio";
				drive-strength = <0x02>;
				bias-pull-up;
				phandle = <0xaa>;
			};

			pac: tlmm-wps-gpio-key-active {
				pins = "gpio27";
				function = "gpio";
				drive-strength = <0x02>;
				bias-pull-up;
				phandle = <0xac>;
			};

			pab: gpio-leds-default-state {
				function = "gpio";
				pins = "gpio70", "gpio71", "gpio72", "gpio73", "gpio0", "gpio1", "gpio91", "gpio100", "gpio14", "gpio12", "gpio119", "gpio114", "gpio32";
				drive-strength = <0x08>;
				bias-disable;
				phandle = <0xab>;
			};

			pa9: usb-id-default-state {
				function = "gpio";
				pins = "gpio110";
				drive-strength = <0x08>;
				bias-pull-up;
				phandle = <0xa9>;
			};
		};

		p13: clock-controller@1800000 {
			compatible = "qcom,gcc-msm8916";
			#clock-cells = <0x01>;
			#reset-cells = <0x01>;
			#power-domain-cells = <0x01>;
			reg = <0x1800000 0x80000>;
			clocks = <&p1b &p4a 0x00 0x00 0x00 0x00 0x00>;
			clock-names = "xo", "sleep_clk", "dsi0pll", "dsi0pllbyte", "ext_mclk", "ext_pri_i2s", "ext_sec_i2s";
			phandle = <0x13>;
		};

		p2: hwlock@1905000 {
			compatible = "qcom,tcsr-mutex";
			reg = <0x1905000 0x20000>;
			#hwlock-cells = <0x01>;
			phandle = <0x02>;
		};

		p14: syscon@1937000 {
			compatible = "qcom,tcsr-msm8916", "syscon";
			reg = <0x1937000 0x30000>;
			phandle = <0x14>;
		};

		p4b: display-subsystem@1a00000 {
			status = "disabled";
			compatible = "qcom,mdss";
			reg = <0x1a00000 0x1000 0x1ac8000 0x3000>;
			reg-names = "mdss_phys", "vbif_phys";
			power-domains = <&p13 0x02>;
			clocks = <&p13 0x6d &p13 0x6e &p13 0x73>;
			clock-names = "iface", "bus", "vsync";
			interrupts = <0x00 0x48 0x04>;
			interrupt-controller;
			#interrupt-cells = <0x01>;
			#address-cells = <0x01>;
			#size-cells = <0x01>;
			ranges;
			phandle = <0x4b>;

			display-controller@1a01000 {
				compatible = "qcom,msm8916-mdp5", "qcom,mdp5";
				reg = <0x1a01000 0x89000>;
				reg-names = "mdp_phys";
				interrupt-parent = <0x4b>;
				interrupts = <0x00>;
				clocks = <&p13 0x6d &p13 0x6e &p13 0x71 &p13 0x73>;
				clock-names = "iface", "bus", "core", "vsync";
				iommus = <&p4c 0x04>;

				ports {
					#address-cells = <0x01>;
					#size-cells = <0x00>;

					port@0 {
						reg = <0x00>;

						p51: endpoint {
							remote-endpoint = <0x4d>;
							phandle = <0x51>;
						};
					};
				};
			};

			dsi@1a98000 {
				compatible = "qcom,msm8916-dsi-ctrl", "qcom,mdss-dsi-ctrl";
				reg = <0x1a98000 0x25c>;
				reg-names = "dsi_ctrl";
				interrupt-parent = <0x4b>;
				interrupts = <0x04>;
				assigned-clocks = <0x13 0x2b 0x13 0x2e>;
				assigned-clock-parents = <0x4e 0x00 0x4e 0x01>;
				clocks = <&p13 0x71 &p13 0x6d &p13 0x6e &p13 0x6f &p13 0x72 &p13 0x70>;
				clock-names = "mdp_core", "iface", "bus", "byte", "pixel", "core";
				phys = <&p4e>;
				#address-cells = <0x01>;
				#size-cells = <0x00>;
				vdda-supply = <0x4f>;
				vddio-supply = <0x50>;

				ports {
					#address-cells = <0x01>;
					#size-cells = <0x00>;

					port@0 {
						reg = <0x00>;

						p4d: endpoint {
							remote-endpoint = <0x51>;
							phandle = <0x4d>;
						};
					};

					port@1 {
						reg = <0x01>;

						endpoint {
						};
					};
				};
			};

			p4e: phy@1a98300 {
				compatible = "qcom,dsi-phy-28nm-lp";
				reg = <0x1a98300 0xd4 0x1a98500 0x280 0x1a98780 0x30>;
				reg-names = "dsi_pll", "dsi_phy", "dsi_phy_regulator";
				#clock-cells = <0x01>;
				#phy-cells = <0x00>;
				clocks = <&p13 0x6d &p1b>;
				clock-names = "iface", "ref";
				vddio-supply = <0x50>;
				phandle = <0x4e>;
			};
		};

		camss@1b00000 {
			compatible = "qcom,msm8916-camss";
			reg = <0x1b0ac00 0x200 0x1b00030 0x04 0x1b0b000 0x200 0x1b00038 0x04 0x1b08000 0x100 0x1b08400 0x100 0x1b0a000 0x500 0x1b00020 0x10 0x1b10000 0x1000>;
			reg-names = "csiphy0", "csiphy0_clk_mux", "csiphy1", "csiphy1_clk_mux", "csid0", "csid1", "ispif", "csi_clk_mux", "vfe0";
			interrupts = <0x00 0x4e 0x01 0x00 0x4f 0x01 0x00 0x33 0x01 0x00 0x34 0x01 0x00 0x37 0x01 0x00 0x39 0x01>;
			interrupt-names = "csiphy0", "csiphy1", "csid0", "csid1", "ispif", "vfe0";
			power-domains = <&p13 0x04>;
			clocks = <&p13 0x60 &p13 0x56 &p13 0x5d &p13 0x5e &p13 0x49 &p13 0x4a &p13 0x4b &p13 0x4c &p13 0x4d &p13 0x4e &p13 0x4f &p13 0x50 &p13 0x51 &p13 0x52 &p13 0x5f &p13 0x63 &p13 0x53 &p13 0x64 &p13 0x65>;
			clock-names = "top_ahb", "ispif_ahb", "csiphy0_timer", "csiphy1_timer", "csi0_ahb", "csi0", "csi0_phy", "csi0_pix", "csi0_rdi", "csi1_ahb", "csi1", "csi1_phy", "csi1_pix", "csi1_rdi", "ahb", "vfe0", "csi_vfe0", "vfe_ahb", "vfe_axi";
			iommus = <&p4c 0x03>;
			status = "disabled";
			vdda-supply = <0x4f>;

			ports {
				#address-cells = <0x01>;
				#size-cells = <0x00>;
			};
		};

		cci@1b0c000 {
			compatible = "qcom,msm8916-cci", "qcom,msm8226-cci";
			#address-cells = <0x01>;
			#size-cells = <0x00>;
			reg = <0x1b0c000 0x1000>;
			interrupts = <0x00 0x32 0x01>;
			clocks = <&p13 0x60 &p13 0x47 &p13 0x48 &p13 0x5f>;
			clock-names = "camss_top_ahb", "cci_ahb", "cci", "camss_ahb";
			assigned-clocks = <0x13 0x47 0x13 0x48>;
			assigned-clock-rates = <0x4c4b400 0x124f800>;
			pinctrl-names = "default";
			pinctrl-0 = <0x52>;
			status = "disabled";

			i2c-bus@0 {
				reg = <0x00>;
				clock-frequency = <0x61a80>;
				#address-cells = <0x01>;
				#size-cells = <0x00>;
			};
		};

		gpu@1c00000 {
			compatible = "qcom,adreno-306.0", "qcom,adreno";
			reg = <0x1c00000 0x20000>;
			reg-names = "kgsl_3d0_reg_memory";
			interrupts = <0x00 0x21 0x04>;
			interrupt-names = "kgsl_3d0_irq";
			clock-names = "core", "iface", "mem", "mem_iface", "alt_mem_iface", "gfx3d";
			clocks = <&p13 0x76 &p13 0x75 &p13 0x69 &p13 0x8e &p13 0x8f &p13 0x0e>;
			power-domains = <&p13 0x05>;
			operating-points-v2 = <0x53>;
			iommus = <&p54 0x01 &p54 0x02>;

			p53: opp-table {
				compatible = "operating-points-v2";
				phandle = <0x53>;

				opp-400000000 {
					opp-hz = <0x00 0x17d78400>;
				};

				opp-19200000 {
					opp-hz = <0x00 0x124f800>;
				};
			};
		};

		video-codec@1d00000 {
			compatible = "qcom,msm8916-venus";
			reg = <0x1d00000 0xff000>;
			interrupts = <0x00 0x2c 0x04>;
			power-domains = <&p13 0x01>;
			clocks = <&p13 0x89 &p13 0x87 &p13 0x88>;
			clock-names = "core", "iface", "bus";
			iommus = <&p4c 0x05>;
			memory-region = <0x55>;
			status = "disabled";

			video-decoder {
				compatible = "venus-decoder";
			};

			video-encoder {
				compatible = "venus-encoder";
			};
		};

		p4c: iommu@1ef0000 {
			#address-cells = <0x01>;
			#size-cells = <0x01>;
			#iommu-cells = <0x01>;
			compatible = "qcom,msm8916-iommu", "qcom,msm-iommu-v1";
			ranges = <0x00 0x1e20000 0x40000>;
			reg = <0x1ef0000 0x3000>;
			clocks = <&p13 0x81 &p13 0x8b>;
			clock-names = "iface", "bus";
			qcom,iommu-secure-id = <0x11>;
			phandle = <0x4c>;

			iommu-ctx@3000 {
				compatible = "qcom,msm-iommu-v1-sec";
				reg = <0x3000 0x1000>;
				interrupts = <0x00 0x46 0x04>;
			};

			iommu-ctx@4000 {
				compatible = "qcom,msm-iommu-v1-ns";
				reg = <0x4000 0x1000>;
				interrupts = <0x00 0x46 0x04>;
			};

			iommu-ctx@5000 {
				compatible = "qcom,msm-iommu-v1-sec";
				reg = <0x5000 0x1000>;
				interrupts = <0x00 0x46 0x04>;
			};
		};

		p54: iommu@1f08000 {
			#address-cells = <0x01>;
			#size-cells = <0x01>;
			#iommu-cells = <0x01>;
			compatible = "qcom,msm8916-iommu", "qcom,msm-iommu-v1";
			ranges = <0x00 0x1f08000 0x10000>;
			clocks = <&p13 0x81 &p13 0x8c>;
			clock-names = "iface", "bus";
			qcom,iommu-secure-id = <0x12>;
			phandle = <0x54>;

			iommu-ctx@1000 {
				compatible = "qcom,msm-iommu-v1-ns";
				reg = <0x1000 0x1000>;
				interrupts = <0x00 0xf1 0x04>;
			};

			iommu-ctx@2000 {
				compatible = "qcom,msm-iommu-v1-ns";
				reg = <0x2000 0x1000>;
				interrupts = <0x00 0xf2 0x04>;
			};
		};

		p5b: spmi@200f000 {
			compatible = "qcom,spmi-pmic-arb";
			reg = <0x200f000 0x1000 0x2400000 0x400000 0x2c00000 0x400000 0x3800000 0x200000 0x200a000 0x2100>;
			reg-names = "core", "chnls", "obsrvr", "intr", "cnfg";
			interrupt-names = "periph_irq";
			interrupts = <0x00 0xbe 0x04>;
			qcom,ee = <0x00>;
			qcom,channel = <0x00>;
			#address-cells = <0x02>;
			#size-cells = <0x00>;
			interrupt-controller;
			#interrupt-cells = <0x04>;
			phandle = <0x5b>;

			pmic@0 {
				compatible = "qcom,pm8916", "qcom,spmi-pmic";
				reg = <0x00 0x00>;
				#address-cells = <0x01>;
				#size-cells = <0x00>;

				pon@800 {
					compatible = "qcom,pm8916-pon";
					reg = <0x800>;
					mode-bootloader = <0x02>;
					mode-recovery = <0x01>;

					pwrkey {
						compatible = "qcom,pm8941-pwrkey";
						interrupts = <0x00 0x08 0x00 0x03>;
						debounce = <0x3d09>;
						bias-pull-up;
						linux,code = <0x74>;
					};

					resin {
						compatible = "qcom,pm8941-resin";
						interrupts = <0x00 0x08 0x01 0x03>;
						debounce = <0x3d09>;
						bias-pull-up;
						status = "disabled";
					};

					watchdog {
						compatible = "qcom,pm8916-wdt";
						interrupts = <0x00 0x08 0x06 0x01>;
						timeout-sec = <0x3c>;
					};
				};

				p58: charger@1000 {
					compatible = "qcom,pm8916-lbc";
					reg = <0x1000 0x1200 0x1300 0x1600>;
					reg-names = "chgr", "bat_if", "usb", "misc";
					interrupts = <0x00 0x10 0x00 0x03 0x00 0x10 0x05 0x03 0x00 0x10 0x06 0x03 0x00 0x10 0x07 0x03 0x00 0x12 0x00 0x03 0x00 0x12 0x01 0x03 0x00 0x13 0x00 0x03 0x00 0x13 0x01 0x03 0x00 0x13 0x02 0x03 0x00 0x13 0x04 0x03>;
					interrupt-names = "vbat_det", "fast_chg", "chg_fail", "chg_done", "bat_pres", "temp_ok", "coarse_det", "usb_vbus", "chg_gone", "overtemp";
					status = "okay";
					qcom,fast-charge-safe-voltage = <0x40d990>;
					qcom,fast-charge-safe-current = <0xaae60>;
					monitored-battery = <0x56>;
					phandle = <0x58>;
				};

				extcon@1300 {
					compatible = "qcom,pm8941-misc";
					reg = <0x1300>;
					interrupts = <0x00 0x13 0x01 0x03>;
					interrupt-names = "usb_vbus";
					status = "disabled";
				};

				temp-alarm@2400 {
					compatible = "qcom,spmi-temp-alarm";
					reg = <0x2400>;
					interrupts = <0x00 0x24 0x00 0x01>;
					io-channels = <&p57 0x08>;
					io-channel-names = "thermal";
					#thermal-sensor-cells = <0x00>;
				};

				p57: adc@3100 {
					compatible = "qcom,spmi-vadc";
					reg = <0x3100>;
					interrupts = <0x00 0x31 0x00 0x01>;
					#address-cells = <0x01>;
					#size-cells = <0x00>;
					#io-channel-cells = <0x01>;
					phandle = <0x57>;

					adc-chan@0 {
						reg = <0x00>;
						qcom,pre-scaling = <0x01 0x0a>;
					};

					adc-chan@7 {
						reg = <0x07>;
						qcom,pre-scaling = <0x01 0x03>;
					};

					adc-chan@8 {
						reg = <0x08>;
					};

					adc-chan@9 {
						reg = <0x09>;
					};

					adc-chan@a {
						reg = <0x0a>;
					};

					adc-chan@e {
						reg = <0x0e>;
					};

					adc-chan@f {
						reg = <0x0f>;
					};
				};

				vm-bms@4000 {
					compatible = "qcom,pm8916-bms-vm";
					reg = <0x4000>;
					interrupts = <0x00 0x40 0x00 0x01 0x00 0x40 0x01 0x01 0x00 0x40 0x02 0x01 0x00 0x40 0x03 0x01 0x00 0x40 0x04 0x01 0x00 0x40 0x05 0x01>;
					interrupt-names = "cv_leave", "cv_enter", "ocv_good", "ocv_thr", "fifo", "state_chg";
					status = "okay";
					monitored-battery = <0x56>;
					power-supplies = <0x58>;
				};

				rtc@6000 {
					compatible = "qcom,pm8941-rtc";
					reg = <0x6000 0x6100>;
					reg-names = "rtc", "alarm";
					interrupts = <0x00 0x61 0x01 0x01>;
				};

				p59: mpps@a000 {
					compatible = "qcom,pm8916-mpp", "qcom,spmi-mpp";
					reg = <0xa000>;
					gpio-controller;
					#gpio-cells = <0x02>;
					gpio-ranges = <0x59 0x00 0x00 0x04>;
					interrupt-controller;
					#interrupt-cells = <0x02>;
					phandle = <0x59>;
				};

				p5a: gpio@c000 {
					compatible = "qcom,pm8916-gpio", "qcom,spmi-gpio";
					reg = <0xc000>;
					gpio-controller;
					gpio-ranges = <0x5a 0x00 0x00 0x04>;
					#gpio-cells = <0x02>;
					interrupt-controller;
					#interrupt-cells = <0x02>;
					phandle = <0x5a>;
				};
			};

			pmic@1 {
				compatible = "qcom,pm8916", "qcom,spmi-pmic";
				reg = <0x01 0x00>;
				#address-cells = <0x01>;
				#size-cells = <0x00>;

				pwm {
					compatible = "qcom,pm8916-pwm";
					#pwm-cells = <0x02>;
					status = "disabled";
				};

				vibrator@c000 {
					compatible = "qcom,pm8916-vib";
					reg = <0xc000>;
					status = "okay";
				};

				p6f: audio-codec@f000 {
					compatible = "qcom,pm8916-wcd-analog-codec";
					reg = <0xf000>;
					reg-names = "pmic-codec-core";
					clocks = <&p13 0x9f>;
					clock-names = "mclk";
					interrupt-parent = <0x5b>;
					interrupts = <0x01 0xf0 0x00 0x00 0x01 0xf0 0x01 0x00 0x01 0xf0 0x02 0x00 0x01 0xf0 0x03 0x00 0x01 0xf0 0x04 0x00 0x01 0xf0 0x05 0x00 0x01 0xf0 0x06 0x00 0x01 0xf0 0x07 0x00 0x01 0xf1 0x00 0x00 0x01 0xf1 0x01 0x00 0x01 0xf1 0x02 0x00 0x01 0xf1 0x03 0x00 0x01 0xf1 0x04 0x00 0x01 0xf1 0x05 0x00>;
					interrupt-names = "cdc_spk_cnp_int", "cdc_spk_clip_int", "cdc_spk_ocp_int", "mbhc_ins_rem_det1", "mbhc_but_rel_det", "mbhc_but_press_det", "mbhc_ins_rem_det", "mbhc_switch_int", "cdc_ear_ocp_int", "cdc_hphr_ocp_int", "cdc_hphl_ocp_det", "cdc_ear_cnp_int", "cdc_hphr_cnp_int", "cdc_hphl_cnp_int";
					vdd-cdc-io-supply = <0x5c>;
					vdd-cdc-tx-rx-cx-supply = <0x5c>;
					vdd-micbias-supply = <0x5d>;
					#sound-dai-cells = <0x01>;
					phandle = <0x6f>;
				};
			};
		};

		p67: dma-controller@4044000 {
			compatible = "qcom,bam-v1.7.0";
			reg = <0x4044000 0x19000>;
			interrupts = <0x00 0x1d 0x04>;
			#dma-cells = <0x01>;
			qcom,ee = <0x00>;
			num-channels = <0x06>;
			qcom,num-ees = <0x01>;
			qcom,powered-remotely;
			status = "okay";
			phandle = <0x67>;
		};

		remoteproc@4080000 {
			compatible = "qcom,msm8916-mss-pil";
			reg = <0x4080000 0x100 0x4020000 0x40>;
			reg-names = "qdsp6", "rmb";
			interrupts-extended = <&p1 0x00 0x18 0x01 &p5e 0x00 0x01 &p5e 0x01 0x01 &p5e 0x02 0x01 &p5e 0x03 0x01>;
			interrupt-names = "wdog", "fatal", "ready", "handover", "stop-ack";
			power-domains = <&p5f 0x00 &p5f 0x03>;
			power-domain-names = "cx", "mx";
			clocks = <&p13 0x74 &p13 0xa0 &p13 0x46 &p1b>;
			clock-names = "iface", "bus", "mem", "xo";
			qcom,smem-states = <0x60 0x00>;
			qcom,smem-state-names = "stop";
			resets = <&p61 0x00>;
			reset-names = "mss_restart";
			qcom,halt-regs = <0x14 0x18000 0x19000 0x1a000>;
			status = "okay";
			pll-supply = <0x62>;

			mba {
				memory-region = <0x63>;
			};

			mpss {
				memory-region = <0x64>;
			};

			bam-dmux {
				compatible = "qcom,bam-dmux";
				interrupt-parent = <0x65>;
				interrupts = <0x01 0x03 0x0b 0x03>;
				interrupt-names = "pc", "pc-ack";
				qcom,smem-states = <0x66 0x01 0x66 0x0b>;
				qcom,smem-state-names = "pc", "pc-ack";
				dmas = <&p67 0x04 &p67 0x05>;
				dma-names = "tx", "rx";
				status = "okay";
			};

			smd-edge {
				interrupts = <0x00 0x19 0x01>;
				qcom,smd-edge = <0x00>;
				qcom,ipc = <0x05 0x08 0x0c>;
				qcom,remote-pid = <0x01>;
				label = "hexagon";

				apr {
					compatible = "qcom,apr-v2";
					qcom,smd-channels = "apr_audio_svc";
					qcom,apr-domain = <0x04>;
					#address-cells = <0x01>;
					#size-cells = <0x00>;
					status = "okay";

					apr-service@3 {
						reg = <0x03>;
						compatible = "qcom,q6core";
					};

					apr-service@4 {
						compatible = "qcom,q6afe";
						reg = <0x04>;

						p6c: dais {
							compatible = "qcom,q6afe-dais";
							#address-cells = <0x01>;
							#size-cells = <0x00>;
							#sound-dai-cells = <0x01>;
							phandle = <0x6c>;

							dai@16 {
								reg = <0x10>;
								qcom,sd-lines = <0x00 0x01>;
							};

							dai@20 {
								reg = <0x15>;
								qcom,sd-lines = <0x00 0x01>;
							};
						};
					};

					apr-service@7 {
						compatible = "qcom,q6asm";
						reg = <0x07>;

						p6a: dais {
							compatible = "qcom,q6asm-dais";
							#address-cells = <0x01>;
							#size-cells = <0x00>;
							#sound-dai-cells = <0x01>;
							phandle = <0x6a>;

							dai@0 {
								reg = <0x00>;
								direction = <0x02>;
							};

							dai@1 {
								reg = <0x01>;
								direction = <0x01>;
							};

							dai@2 {
								reg = <0x02>;
								direction = <0x02>;
							};

							dai@3 {
								reg = <0x03>;
								direction = <0x02>;
								is-compress-dai;
							};
						};
					};

					apr-service@8 {
						compatible = "qcom,q6adm";
						reg = <0x08>;

						p6d: routing {
							compatible = "qcom,q6adm-routing";
							#sound-dai-cells = <0x00>;
							phandle = <0x6d>;
						};
					};

					apr-service@9 {
						compatible = "qcom,q6mvm";
						reg = <0x09>;

						p6b: dais {
							compatible = "qcom,q6voice-dais";
							#sound-dai-cells = <0x00>;
							phandle = <0x6b>;
						};
					};

					apr-service@a {
						compatible = "qcom,q6cvs";
						reg = <0x0a>;
					};

					apr-service@b {
						compatible = "qcom,q6cvp";
						reg = <0x0b>;
					};
				};

				fastrpc {
					compatible = "qcom,fastrpc";
					qcom,smd-channels = "fastrpcsmd-apps-dsp";
					label = "adsp";
					qcom,non-secure-domain;
					#address-cells = <0x01>;
					#size-cells = <0x00>;

					cb@1 {
						compatible = "qcom,fastrpc-compute-cb";
						reg = <0x01>;
					};
				};
			};
		};

		sound@7702000 {
			status = "disabled";
			compatible = "qcom,msm8916-qdsp6-sndcard";
			reg = <0x7702000 0x04 0x7702004 0x04>;
			reg-names = "mic-iomux", "spkr-iomux";
			model = "msm8916";
			pinctrl-names = "default", "sleep";
			pinctrl-0 = <0x68>;
			pinctrl-1 = <0x69>;

			dai-link-multimedia1 {
				link-name = "MultiMedia1";

				cpu {
					sound-dai = <&p6a 0x00>;
				};
			};

			dai-link-multimedia2 {
				link-name = "MultiMedia2";

				cpu {
					sound-dai = <&p6a 0x01>;
				};
			};

			dai-link-multimedia3 {
				link-name = "MultiMedia3";

				cpu {
					sound-dai = <&p6a 0x02>;
				};
			};

			dai-link-multimedia4 {
				link-name = "MultiMedia4";

				cpu {
					sound-dai = <&p6a 0x03>;
				};
			};

			dai-link-cs-voice {
				link-name = "CS-Voice";

				cpu {
					sound-dai = <&p6b 0x00>;
				};
			};

			dai-link-primary {
				link-name = "Primary MI2S";

				cpu {
					sound-dai = <&p6c 0x10>;
				};

				platform {
					sound-dai = <&p6d>;
				};

				codec {
					sound-dai = <&p6e 0x00 &p6f 0x00>;
				};
			};

			dai-link-secondary {
				link-name = "Secondary MI2S";
				status = "disabled";

				cpu {
					sound-dai = <&p6c 0x12>;
				};

				platform {
					sound-dai = <&p6d>;
				};
			};

			dai-link-tertiary {
				link-name = "Tertiary MI2S";

				cpu {
					sound-dai = <&p6c 0x15>;
				};

				platform {
					sound-dai = <&p6d>;
				};

				codec {
					sound-dai = <&p6e 0x01 &p6f 0x01>;
				};
			};

			dai-link-quaternary {
				link-name = "Quaternary MI2S";
				status = "disabled";

				cpu {
					sound-dai = <&p6c 0x16>;
				};

				platform {
					sound-dai = <&p6d>;
				};
			};
		};

		audio-controller@7708000 {
			status = "okay";
			compatible = "qcom,apq8016-lpass-cpu";
			clocks = <&p13 0x9a &p13 0x96 &p13 0x97 &p13 0x9c &p13 0x9c &p13 0x9d &p13 0x9e>;
			clock-names = "ahbix-clk", "pcnoc-mport-clk", "pcnoc-sway-clk", "mi2s-bit-clk0", "mi2s-bit-clk1", "mi2s-bit-clk2", "mi2s-bit-clk3";
			#sound-dai-cells = <0x01>;
			interrupts = <0x00 0xa0 0x04>;
			interrupt-names = "lpass-irq-lpaif";
			reg = <0x7708000 0x10000>;
			reg-names = "lpass-lpaif";
			#address-cells = <0x01>;
			#size-cells = <0x00>;
		};

		p6e: audio-codec@771c000 {
			compatible = "qcom,msm8916-wcd-digital-codec";
			reg = <0x771c000 0x400>;
			clocks = <&p13 0x9a &p13 0x9f>;
			clock-names = "ahbix-clk", "mclk";
			#sound-dai-cells = <0x01>;
			phandle = <0x6e>;
		};

		mmc@7824000 {
			compatible = "qcom,msm8916-sdhci", "qcom,sdhci-msm-v4";
			reg = <0x7824900 0x11c 0x7824000 0x800>;
			reg-names = "hc", "core";
			interrupts = <0x00 0x7b 0x04 0x00 0x8a 0x04>;
			interrupt-names = "hc_irq", "pwr_irq";
			clocks = <&p13 0x7a &p13 0x7b &p1b>;
			clock-names = "iface", "core", "xo";
			mmc-ddr-1_8v;
			bus-width = <0x08>;
			non-removable;
			status = "okay";
			vmmc-supply = <0x70>;
			vqmmc-supply = <0x5c>;
			pinctrl-0 = <0x71 0x72 0x73>;
			pinctrl-1 = <0x74 0x75 0x76>;
			pinctrl-names = "default", "sleep";
		};

		mmc@7864000 {
			compatible = "qcom,msm8916-sdhci", "qcom,sdhci-msm-v4";
			reg = <0x7864900 0x11c 0x7864000 0x800>;
			reg-names = "hc", "core";
			interrupts = <0x00 0x7d 0x04 0x00 0xdd 0x04>;
			interrupt-names = "hc_irq", "pwr_irq";
			clocks = <&p13 0x7c &p13 0x7d &p1b>;
			clock-names = "iface", "core", "xo";
			bus-width = <0x04>;
			status = "okay";
			vmmc-supply = <0x77>;
			vqmmc-supply = <0x78>;
			pinctrl-names = "default", "sleep";
			pinctrl-0 = <0x79 0x7a 0x7b 0x1000>;
			pinctrl-1 = <0x7c 0x7d 0x7e 0x1000>;
			cd-gpios = <&p49 0x26 0x01>;
		};

		p7f: dma-controller@7884000 {
			compatible = "qcom,bam-v1.7.0";
			reg = <0x7884000 0x23000>;
			interrupts = <0x00 0xee 0x04>;
			clocks = <&p13 0x36>;
			clock-names = "bam_clk";
			#dma-cells = <0x01>;
			qcom,ee = <0x00>;
			status = "okay";
			phandle = <0x7f>;
		};

		serial@78af000 {
			compatible = "qcom,msm-uartdm-v1.4", "qcom,msm-uartdm";
			reg = <0x78af000 0x200>;
			interrupts = <0x00 0x6b 0x04>;
			clocks = <&p13 0x44 &p13 0x36>;
			clock-names = "core", "iface";
			dmas = <&p7f 0x00 &p7f 0x01>;
			dma-names = "tx", "rx";
			pinctrl-names = "default", "sleep";
			pinctrl-0 = <0x80>;
			pinctrl-1 = <0x81>;
			status = "disabled";
		};

		serial@78b0000 {
			compatible = "qcom,msm-uartdm-v1.4", "qcom,msm-uartdm";
			reg = <0x78b0000 0x200>;
			interrupts = <0x00 0x6c 0x04>;
			clocks = <&p13 0x45 &p13 0x36>;
			clock-names = "core", "iface";
			dmas = <&p7f 0x02 &p7f 0x03>;
			dma-names = "tx", "rx";
			pinctrl-names = "default", "sleep";
			pinctrl-0 = <0x82>;
			pinctrl-1 = <0x83>;
			status = "okay";
		};

		i2c@78b5000 {
			compatible = "qcom,i2c-qup-v2.2.1";
			reg = <0x78b5000 0x500>;
			interrupts = <0x00 0x5f 0x04>;
			clocks = <&p13 0x38 &p13 0x36>;
			clock-names = "core", "iface";
			dmas = <&p7f 0x04 &p7f 0x05>;
			dma-names = "tx", "rx";
			pinctrl-names = "default", "sleep";
			pinctrl-0 = <0x84>;
			pinctrl-1 = <0x85>;
			#address-cells = <0x01>;
			#size-cells = <0x00>;
			status = "disabled";
		};

		spi@78b5000 {
			compatible = "qcom,spi-qup-v2.2.1";
			reg = <0x78b5000 0x500>;
			interrupts = <0x00 0x5f 0x04>;
			clocks = <&p13 0x39 &p13 0x36>;
			clock-names = "core", "iface";
			dmas = <&p7f 0x04 &p7f 0x05>;
			dma-names = "tx", "rx";
			pinctrl-names = "default", "sleep";
			pinctrl-0 = <0x86>;
			pinctrl-1 = <0x87>;
			#address-cells = <0x01>;
			#size-cells = <0x00>;
			status = "disabled";
		};

		i2c@78b6000 {
			compatible = "qcom,i2c-qup-v2.2.1";
			reg = <0x78b6000 0x500>;
			interrupts = <0x00 0x60 0x04>;
			clocks = <&p13 0x3a &p13 0x36>;
			clock-names = "core", "iface";
			dmas = <&p7f 0x06 &p7f 0x07>;
			dma-names = "tx", "rx";
			pinctrl-names = "default", "sleep";
			pinctrl-0 = <0x88>;
			pinctrl-1 = <0x89>;
			#address-cells = <0x01>;
			#size-cells = <0x00>;
			status = "disabled";
		};

		spi@78b6000 {
			compatible = "qcom,spi-qup-v2.2.1";
			reg = <0x78b6000 0x500>;
			interrupts = <0x00 0x60 0x04>;
			clocks = <&p13 0x3b &p13 0x36>;
			clock-names = "core", "iface";
			dmas = <&p7f 0x06 &p7f 0x07>;
			dma-names = "tx", "rx";
			pinctrl-names = "default", "sleep";
			pinctrl-0 = <0x8a>;
			pinctrl-1 = <0x8b>;
			#address-cells = <0x01>;
			#size-cells = <0x00>;
			status = "disabled";
		};

		i2c@78b7000 {
			compatible = "qcom,i2c-qup-v2.2.1";
			reg = <0x78b7000 0x500>;
			interrupts = <0x00 0x61 0x04>;
			clocks = <&p13 0x3c &p13 0x36>;
			clock-names = "core", "iface";
			dmas = <&p7f 0x08 &p7f 0x09>;
			dma-names = "tx", "rx";
			pinctrl-names = "default", "sleep";
			pinctrl-0 = <0x8c>;
			pinctrl-1 = <0x8d>;
			#address-cells = <0x01>;
			#size-cells = <0x00>;
			status = "disabled";
		};

		spi@78b7000 {
			compatible = "qcom,spi-qup-v2.2.1";
			reg = <0x78b7000 0x500>;
			interrupts = <0x00 0x61 0x04>;
			clocks = <&p13 0x3d &p13 0x36>;
			clock-names = "core", "iface";
			dmas = <&p7f 0x08 &p7f 0x09>;
			dma-names = "tx", "rx";
			pinctrl-names = "default", "sleep";
			pinctrl-0 = <0x8e>;
			pinctrl-1 = <0x8f>;
			#address-cells = <0x01>;
			#size-cells = <0x00>;
			status = "disabled";
		};

		i2c@78b8000 {
			compatible = "qcom,i2c-qup-v2.2.1";
			reg = <0x78b8000 0x500>;
			interrupts = <0x00 0x62 0x04>;
			clocks = <&p13 0x3e &p13 0x36>;
			clock-names = "core", "iface";
			dmas = <&p7f 0x0a &p7f 0x0b>;
			dma-names = "tx", "rx";
			pinctrl-names = "default", "sleep";
			pinctrl-0 = <0x90>;
			pinctrl-1 = <0x91>;
			#address-cells = <0x01>;
			#size-cells = <0x00>;
			status = "disabled";
		};

		spi@78b8000 {
			compatible = "qcom,spi-qup-v2.2.1";
			reg = <0x78b8000 0x500>;
			interrupts = <0x00 0x62 0x04>;
			clocks = <&p13 0x3f &p13 0x36>;
			clock-names = "core", "iface";
			dmas = <&p7f 0x0a &p7f 0x0b>;
			dma-names = "tx", "rx";
			pinctrl-names = "default", "sleep";
			pinctrl-0 = <0x92>;
			pinctrl-1 = <0x93>;
			#address-cells = <0x01>;
			#size-cells = <0x00>;
			status = "disabled";
		};

		i2c@78b9000 {
			compatible = "qcom,i2c-qup-v2.2.1";
			reg = <0x78b9000 0x500>;
			interrupts = <0x00 0x63 0x04>;
			clocks = <&p13 0x40 &p13 0x36>;
			clock-names = "core", "iface";
			dmas = <&p7f 0x0c &p7f 0x0d>;
			dma-names = "tx", "rx";
			pinctrl-names = "default", "sleep";
			pinctrl-0 = <0x94>;
			pinctrl-1 = <0x95>;
			#address-cells = <0x01>;
			#size-cells = <0x00>;
			status = "disabled";
		};

		spi@78b9000 {
			compatible = "qcom,spi-qup-v2.2.1";
			reg = <0x78b9000 0x500>;
			interrupts = <0x00 0x63 0x04>;
			clocks = <&p13 0x41 &p13 0x36>;
			clock-names = "core", "iface";
			dmas = <&p7f 0x0c &p7f 0x0d>;
			dma-names = "tx", "rx";
			pinctrl-names = "default", "sleep";
			pinctrl-0 = <0x96>;
			pinctrl-1 = <0x97>;
			#address-cells = <0x01>;
			#size-cells = <0x00>;
			status = "disabled";
		};

		i2c@78ba000 {
			compatible = "qcom,i2c-qup-v2.2.1";
			reg = <0x78ba000 0x500>;
			interrupts = <0x00 0x64 0x04>;
			clocks = <&p13 0x42 &p13 0x36>;
			clock-names = "core", "iface";
			dmas = <&p7f 0x0e &p7f 0x0f>;
			dma-names = "tx", "rx";
			pinctrl-names = "default", "sleep";
			pinctrl-0 = <0x98>;
			pinctrl-1 = <0x99>;
			#address-cells = <0x01>;
			#size-cells = <0x00>;
			status = "disabled";
		};

		spi@78ba000 {
			compatible = "qcom,spi-qup-v2.2.1";
			reg = <0x78ba000 0x500>;
			interrupts = <0x00 0x64 0x04>;
			clocks = <&p13 0x43 &p13 0x36>;
			clock-names = "core", "iface";
			dmas = <&p7f 0x0e &p7f 0x0f>;
			dma-names = "tx", "rx";
			pinctrl-names = "default", "sleep";
			pinctrl-0 = <0x9a>;
			pinctrl-1 = <0x9b>;
			#address-cells = <0x01>;
			#size-cells = <0x00>;
			status = "disabled";
		};

		p9e: usb@78d9000 {
			compatible = "qcom,ci-hdrc";
			reg = <0x78d9000 0x200 0x78d9200 0x200>;
			interrupts = <0x00 0x86 0x04 0x00 0x8c 0x04>;
			clocks = <&p13 0x85 &p13 0x86>;
			clock-names = "iface", "core";
			assigned-clocks = <0x13 0x86>;
			assigned-clock-rates = <0x4c4b400>;
			resets = <&p13 0x22>;
			reset-names = "core";
			phy_type = "ulpi";
			dr_mode = "otg";
			hnp-disable;
			srp-disable;
			adp-disable;
			ahb-burst-config = <0x00>;
			phy-names = "usb-phy";
			phys = <&p9c>;
			status = "okay";
			#reset-cells = <0x01>;
			extcon = <0x9d 0x9d>;
			phandle = <0x9e>;

			ulpi {

				p9c: phy {
					compatible = "qcom,usb-hs-phy-msm8916", "qcom,usb-hs-phy";
					#phy-cells = <0x00>;
					clocks = <&p1b &p13 0x84>;
					clock-names = "ref", "sleep";
					resets = <&p13 0x23 &p9e 0x00>;
					reset-names = "phy", "por";
					qcom,init-seq = [00 44 00 00 00 01 00 00 00 6b 00 00 00 02 00 00 00 24 00 00 00 03 00 00 00 13];
					v1p8-supply = <0x62>;
					v3p3-supply = <0x5d>;
					extcon = <0x9d>;
					phandle = <0x9c>;
				};
			};
		};

		pa4: remoteproc@a21b000 {
			compatible = "qcom,pronto-v2-pil", "qcom,pronto";
			reg = <0xa204000 0x2000 0xa202000 0x1000 0xa21b000 0x3000>;
			reg-names = "ccu", "dxe", "pmu";
			memory-region = <0x9f>;
			interrupts-extended = <&p1 0x00 0x95 0x01 &pa0 0x00 0x01 &pa0 0x01 0x01 &pa0 0x02 0x01 &pa0 0x03 0x01>;
			interrupt-names = "wdog", "fatal", "ready", "handover", "stop-ack";
			power-domains = <&p5f 0x00 &p5f 0x03>;
			power-domain-names = "cx", "mx";
			qcom,smem-states = <0xa1 0x00>;
			qcom,smem-state-names = "stop";
			pinctrl-names = "default";
			pinctrl-0 = <0xa2>;
			status = "okay";
			vddpx-supply = <0x62>;
			phandle = <0xa4>;

			iris {
				clocks = <&p1f 0x10>;
				clock-names = "xo";
				vddxo-supply = <0x62>;
				vddrfa-supply = <0x1d>;
				vddpa-supply = <0xa3>;
				vdddig-supply = <0x5c>;
				compatible = "qcom,wcn3620";
			};

			smd-edge {
				interrupts = <0x00 0x8e 0x01>;
				qcom,ipc = <0x05 0x08 0x11>;
				qcom,smd-edge = <0x06>;
				qcom,remote-pid = <0x04>;
				label = "pronto";

				wcnss {
					compatible = "qcom,wcnss";
					qcom,smd-channels = "WCNSS_CTRL";
					qcom,mmio = <0xa4>;

					bluetooth {
						compatible = "qcom,wcnss-bt";
					};

					wifi {
						compatible = "qcom,wcnss-wlan";
						interrupts = <0x00 0x91 0x04 0x00 0x92 0x04>;
						interrupt-names = "tx", "rx";
						qcom,smem-states = <0x66 0x0a 0x66 0x09>;
						qcom,smem-state-names = "tx-enable", "tx-rings-empty";
					};
				};
			};
		};

		p1: interrupt-controller@b000000 {
			compatible = "qcom,msm-qgic2";
			interrupt-controller;
			#interrupt-cells = <0x03>;
			reg = <0xb000000 0x1000 0xb002000 0x2000 0xb001000 0x1000 0xb004000 0x2000>;
			interrupts = <0x01 0x00 0xf04>;
			phandle = <0x01>;
		};

		p5: mailbox@b011000 {
			compatible = "qcom,msm8916-apcs-kpss-global", "syscon";
			reg = <0xb011000 0x1000>;
			#mbox-cells = <0x01>;
			clocks = <&pa5 &p13 0x01>;
			clock-names = "pll", "aux";
			#clock-cells = <0x00>;
			phandle = <0x05>;
		};

		pa5: clock@b016000 {
			compatible = "qcom,msm8916-a53pll";
			reg = <0xb016000 0x40>;
			#clock-cells = <0x00>;
			clocks = <&p1b>;
			clock-names = "xo";
			phandle = <0xa5>;
		};

		timer@b020000 {
			#address-cells = <0x01>;
			#size-cells = <0x01>;
			ranges;
			compatible = "arm,armv7-timer-mem";
			reg = <0xb020000 0x1000>;
			clock-frequency = <0x124f800>;

			frame@b021000 {
				frame-number = <0x00>;
				interrupts = <0x00 0x08 0x04 0x00 0x07 0x04>;
				reg = <0xb021000 0x1000 0xb022000 0x1000>;
			};

			frame@b023000 {
				frame-number = <0x01>;
				interrupts = <0x00 0x09 0x04>;
				reg = <0xb023000 0x1000>;
				status = "disabled";
			};

			frame@b024000 {
				frame-number = <0x02>;
				interrupts = <0x00 0x0a 0x04>;
				reg = <0xb024000 0x1000>;
				status = "disabled";
			};

			frame@b025000 {
				frame-number = <0x03>;
				interrupts = <0x00 0x0b 0x04>;
				reg = <0xb025000 0x1000>;
				status = "disabled";
			};

			frame@b026000 {
				frame-number = <0x04>;
				interrupts = <0x00 0x0c 0x04>;
				reg = <0xb026000 0x1000>;
				status = "disabled";
			};

			frame@b027000 {
				frame-number = <0x05>;
				interrupts = <0x00 0x0d 0x04>;
				reg = <0xb027000 0x1000>;
				status = "disabled";
			};

			frame@b028000 {
				frame-number = <0x06>;
				interrupts = <0x00 0x0e 0x04>;
				reg = <0xb028000 0x1000>;
				status = "disabled";
			};
		};

		p8: power-manager@b088000 {
			compatible = "qcom,msm8916-acc";
			reg = <0xb088000 0x1000>;
			status = "reserved";
			phandle = <0x08>;
		};

		p9: power-manager@b089000 {
			compatible = "qcom,msm8916-saw2-v3.0-cpu", "qcom,saw2";
			reg = <0xb089000 0x1000>;
			status = "reserved";
			phandle = <0x09>;
		};

		pb: power-manager@b098000 {
			compatible = "qcom,msm8916-acc";
			reg = <0xb098000 0x1000>;
			status = "reserved";
			phandle = <0x0b>;
		};

		pc: power-manager@b099000 {
			compatible = "qcom,msm8916-saw2-v3.0-cpu", "qcom,saw2";
			reg = <0xb099000 0x1000>;
			status = "reserved";
			phandle = <0x0c>;
		};

		pe: power-manager@b0a8000 {
			compatible = "qcom,msm8916-acc";
			reg = <0xb0a8000 0x1000>;
			status = "reserved";
			phandle = <0x0e>;
		};

		pf: power-manager@b0a9000 {
			compatible = "qcom,msm8916-saw2-v3.0-cpu", "qcom,saw2";
			reg = <0xb0a9000 0x1000>;
			status = "reserved";
			phandle = <0x0f>;
		};

		p11: power-manager@b0b8000 {
			compatible = "qcom,msm8916-acc";
			reg = <0xb0b8000 0x1000>;
			status = "reserved";
			phandle = <0x11>;
		};

		p12: power-manager@b0b9000 {
			compatible = "qcom,msm8916-saw2-v3.0-cpu", "qcom,saw2";
			reg = <0xb0b9000 0x1000>;
			status = "reserved";
			phandle = <0x12>;
		};
	};

	thermal-zones {

		cpu0-1-thermal {
			polling-delay-passive = <0xfa>;
			polling-delay = <0x3e8>;
			thermal-sensors = <&pa6 0x05>;

			trips {

				pa7: trip-point0 {
					temperature = <0x124f8>;
					hysteresis = <0x7d0>;
					type = "passive";
					phandle = <0xa7>;
				};

				cpu-crit {
					temperature = <0x1adb0>;
					hysteresis = <0x7d0>;
					type = "critical";
				};
			};

			cooling-maps {

				map0 {
					trip = <0xa7>;
					cooling-device = <&p3d 0xffffffff 0xffffffff &p3e 0xffffffff 0xffffffff &p3f 0xffffffff 0xffffffff &p40 0xffffffff 0xffffffff>;
				};
			};
		};

		cpu2-3-thermal {
			polling-delay-passive = <0xfa>;
			polling-delay = <0x3e8>;
			thermal-sensors = <&pa6 0x04>;

			trips {

				pa8: trip-point0 {
					temperature = <0x124f8>;
					hysteresis = <0x7d0>;
					type = "passive";
					phandle = <0xa8>;
				};

				cpu-crit {
					temperature = <0x1adb0>;
					hysteresis = <0x7d0>;
					type = "critical";
				};
			};

			cooling-maps {

				map0 {
					trip = <0xa8>;
					cooling-device = <&p3d 0xffffffff 0xffffffff &p3e 0xffffffff 0xffffffff &p3f 0xffffffff 0xffffffff &p40 0xffffffff 0xffffffff>;
				};
			};
		};

		gpu-thermal {
			polling-delay-passive = <0xfa>;
			polling-delay = <0x3e8>;
			thermal-sensors = <&pa6 0x02>;

			trips {

				trip-point0 {
					temperature = <0x124f8>;
					hysteresis = <0x7d0>;
					type = "passive";
				};

				gpu-crit {
					temperature = <0x17318>;
					hysteresis = <0x7d0>;
					type = "critical";
				};
			};
		};

		camera-thermal {
			polling-delay-passive = <0xfa>;
			polling-delay = <0x3e8>;
			thermal-sensors = <&pa6 0x01>;

			trips {

				trip-point0 {
					temperature = <0x124f8>;
					hysteresis = <0x7d0>;
					type = "hot";
				};
			};
		};

		modem-thermal {
			polling-delay-passive = <0xfa>;
			polling-delay = <0x3e8>;
			thermal-sensors = <&pa6 0x00>;

			trips {

				trip-point0 {
					temperature = <0x14c08>;
					hysteresis = <0x7d0>;
					type = "hot";
				};
			};
		};
	};

	timer {
		compatible = "arm,armv8-timer";
		interrupts = <0x01 0x02 0xf08 0x01 0x03 0xf08 0x01 0x04 0xf08 0x01 0x01 0xf08>;
	};

	p56: battery {
		compatible = "simple-battery";
		voltage-min-design-microvolt = <0x2dc6c0>;
		voltage-max-design-microvolt = <0x426030>;
		energy-full-design-microwatt-hours = <0x79c3e0>;
		charge-full-design-microamp-hours = <0x200b20>;
		ocv-capacity-celsius = <0x19>;
		ocv-capacity-table-0 = <0x426030 0x64 0x419ce0 0x62 0x40d990 0x60 0x401640 0x5e 0x3e8fa0 0x5a 0x3dcc50 0x57 0x3d0900 0x54 0x3c45b0 0x50 0x3b8260 0x4b 0x3abf10 0x46 0x39fbc0 0x41 0x393870 0x3c 0x387520 0x37 0x37b1d0 0x32 0x36ee80 0x2d 0x362b30 0x28 0x3567e0 0x23 0x34a490 0x1e 0x33e140 0x19 0x331df0 0x14 0x325aa0 0x0f 0x319750 0x0a 0x30d400 0x05 0x3010b0 0x03 0x2f4d60 0x01 0x2dc6c0 0x00>;
		phandle = <0x56>;
	};

	p9d: usb-id {
		compatible = "linux,extcon-usb-gpio";
		id-gpio = <&p49 0x6e 0x00>;
		pinctrl-names = "default";
		pinctrl-0 = <0xa9>;
		phandle = <0x9d>;
	};

	gpio-keys {
		compatible = "gpio-keys";
		pinctrl-names = "default";
		pinctrl-0 = <0xaa 0xac>;
		label = "GPIO Buttons";

		key-freset {
			label = "key_freset";
			gpios = <&p49 0x25 0x00>;
			linux,input-type = <0x01>;
			linux,code = <0xd8>;
			linux,can-wakeup;
			debounce-interval = <0x3c>;
		};

		key-wps {
			label = "key_wps";
			gpios = <&p49 0x1b 0x01>;
			linux,input-type = <0x01>;
			linux,code = <0x40>;
			linux,can-wakeup;
			debounce-interval = <0x3c>;
		};
	};

	leds {
		compatible = "gpio-leds";
		pinctrl-0 = <0xab>;
		pinctrl-names = "default";

		ftest {
			label = "ftest";
			gpios = <&p49 0x20 0x00>;
			linux,default-trigger = "none";
			default-state = "keep";
			retain-state-suspended;
		};

		wifistatus {
			label = "wifistatus";
			gpios = <&p49 0x49 0x00>;
			linux,default-trigger = "none";
			default-state = "off";
			retain-state-suspended;
		};

		led-4g-1 {
			label = "4g_1";
			gpios = <&p49 0x47 0x00>;
			linux,default-trigger = "none";
			default-state = "off";
			retain-state-suspended;
		};

		led-4g-2 {
			label = "4g_2";
			gpios = <&p49 0x46 0x00>;
			linux,default-trigger = "none";
			default-state = "off";
			retain-state-suspended;
		};

		led-4g-type {
			label = "4g_type";
			gpios = <&p49 0x48 0x00>;
			linux,default-trigger = "none";
			default-state = "off";
			retain-state-suspended;
		};

		esim1-en {
			label = "esim1_en";
			gpios = <&p49 0x77 0x00>;
			linux,default-trigger = "none";
			default-state = "keep";
			retain-state-suspended;
		};

		esim2-en {
			label = "esim2_en";
			gpios = <&p49 0x0e 0x00>;
			linux,default-trigger = "none";
			default-state = "keep";
			retain-state-suspended;
		};

		esim3-en {
			label = "esim3_en";
			gpios = <&p49 0x0c 0x00>;
			linux,default-trigger = "none";
			default-state = "keep";
			retain-state-suspended;
		};

		sim-hotplug {
			label = "sim_hotplug";
			gpios = <&p49 0x72 0x00>;
			linux,default-trigger = "none";
			default-state = "keep";
			retain-state-suspended;
		};

		bat-1 {
			label = "bat1";
			gpios = <&p49 0x00 0x00>;
			linux,default-trigger = "none";
			default-state = "off";
			retain-state-suspended;
		};

		bat-2 {
			label = "batl2";
			gpios = <&p49 0x5b 0x00>;
			linux,default-trigger = "none";
			default-state = "off";
			retain-state-suspended;
		};

		bat-3 {
			label = "batl3";
			gpios = <&p49 0x01 0x00>;
			linux,default-trigger = "none";
			default-state = "off";
			retain-state-suspended;
		};

		bat-4 {
			label = "batl4";
			gpios = <&p49 0x64 0x00>;
			linux,default-trigger = "none";
			default-state = "off";
			retain-state-suspended;
		};
	};
};
